VERSION ""

NS_ :

BS_:

BU_: CGW CLU EPB FCA SCC FR_CMR FR_RDR ADAS_PRK AMP BCW LDW_LKA MDPS RVM HUD AVM ACU ESC AFS

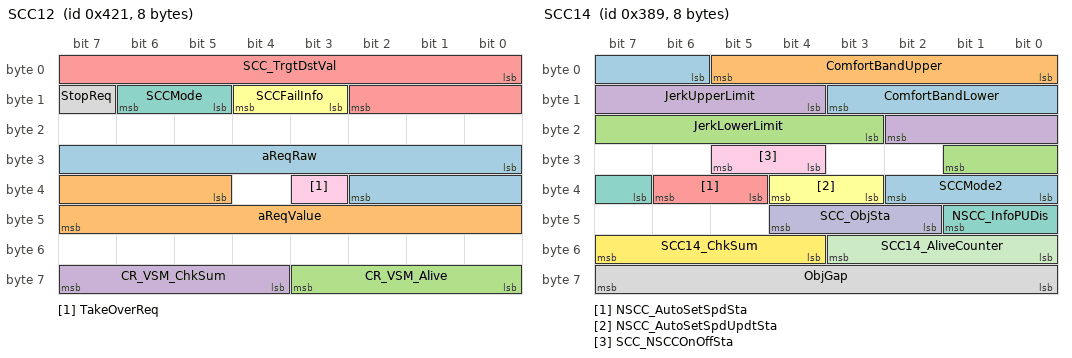
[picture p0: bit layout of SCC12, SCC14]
BO_ 1057 SCC12: 8 SCC
 SG_ aReqRaw : 24|11@1+ (0.01,-10.23) [-10.23|10.24] "m/s^2"  CGW,ESC,FR_CMR
 SG_ aReqValue : 37|11@1+ (0.01,-10.23) [-10.23|10.24] "m/s^2"  CGW,ESC,FR_CMR
 SG_ CR_VSM_Alive : 56|4@1+ (1,0) [0|15] ""  CGW,ESC,FR_CMR
 SG_ CR_VSM_ChkSum : 60|4@1+ (1,0) [0|15] ""  CGW,ESC,FR_CMR
 SG_ SCC_TrgtDstVal : 0|11@1+ (0.1,0) [0|204.7] "m"  CLU,FR_CMR
 SG_ SCCFailInfo : 11|2@1+ (1,0) [0|3] ""  ACU,CGW,CLU,ESC,LDW_LKA,FR_CMR
 SG_ SCCMode : 13|2@1+ (1,0) [0|3] ""  CGW,ESC,LDW_LKA,FR_CMR
 SG_ StopReq : 15|1@1+ (1,0) [0|1] ""  CGW,ESC,FR_CMR
 SG_ TakeOverReq : 35|1@1+ (1,0) [0|1] ""  CGW,CLU,ESC,FR_CMR

BO_ 1290 SCC13: 8 SCC
 SG_ SCC_Equip : 3|1@1+ (1,0) [0|1] ""  ESC,FR_CMR
 SG_ SCCDrvModeRValue : 0|3@1+ (1,0) [0|7] ""  CGW,FR_CMR

BO_ 905 SCC14: 8 SCC
 SG_ ComfortBandLower : 6|6@1+ (0.02,0) [0|1.26] "m/s^2"  ESC,FR_CMR
 SG_ ComfortBandUpper : 0|6@1+ (0.02,0) [0|1.26] "m/s^2"  ESC,FR_CMR
 SG_ JerkLowerLimit : 19|7@1+ (0.1,0) [0|12.7] "m/s^3"  ESC,FR_CMR
 SG_ JerkUpperLimit : 12|7@1+ (0.1,0) [0|12.7] "m/s^3"  ESC,FR_CMR
 SG_ NSCC_AutoSetSpdSta : 37|2@1+ (1,0) [0|1] ""  CGW,CLU,LDW_LKA,FR_CMR
 SG_ NSCC_AutoSetSpdUpdtSta : 35|2@1+ (1,0) [0|1] ""  CGW,CLU,FR_CMR
 SG_ NSCC_InfoPUDis : 39|3@1+ (1,0) [0|7] ""  CGW,CLU,FR_CMR
 SG_ ObjGap : 56|8@1+ (1,0) [0|255] ""  CGW,CLU,ESC,FR_CMR
 SG_ SCC_NSCCOnOffSta : 28|2@1+ (1,0) [0|3] ""  CGW,CLU,FR_CMR
 SG_ SCC_ObjSta : 42|3@1+ (1,0) [0|7] ""  CLU,FR_CMR
 SG_ SCC14_AliveCounter : 48|4@1+ (1,0) [0|15] ""  FR_CMR
 SG_ SCC14_ChkSum : 52|4@1+ (1,0) [0|15] ""  FR_CMR
 SG_ SCCMode2 : 32|3@1+ (1,0) [0|7] ""  ACU,CGW,CLU,ESC,LDW_LKA,FR_CMR

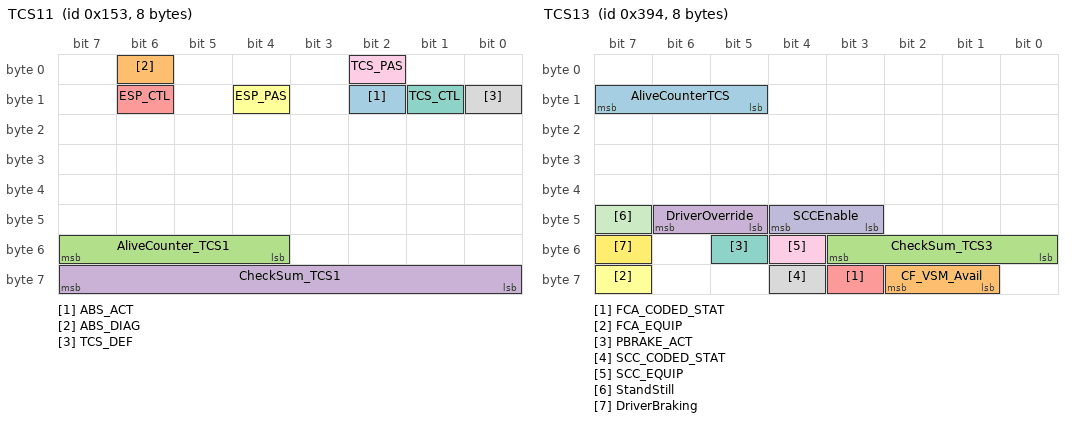
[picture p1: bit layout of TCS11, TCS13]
BO_ 339 TCS11: 8 ESC
 SG_ ABS_ACT : 10|1@1+ (1,0) [0|1] ""  ADAS_PRK,BCW,CGW,EPB,FCA,LDW_LKA,SCC,FR_CMR,FR_RDR
 SG_ ABS_DIAG : 6|1@1+ (1,0) [0|1] ""  ADAS_PRK,BCW,CGW,EPB,FCA,LDW_LKA,SCC,FR_CMR,FR_RDR
 SG_ AliveCounter_TCS1 : 52|4@1+ (1,0) [0|14] ""  CGW,EPB,FCA,SCC,FR_CMR,FR_RDR
 SG_ CheckSum_TCS1 : 56|8@1+ (1,0) [0|255] ""  CGW,EPB,FCA,SCC,FR_CMR,FR_RDR
 SG_ ESP_CTL : 14|1@1+ (1,0) [0|1] ""  ADAS_PRK,BCW,CGW,EPB,FCA,LDW_LKA,SCC,FR_CMR,FR_RDR
 SG_ ESP_PAS : 12|1@1+ (1,0) [0|1] ""  ADAS_PRK,CGW,EPB,FCA,SCC,FR_CMR,FR_RDR
 SG_ TCS_CTL : 9|1@1+ (1,0) [0|1] ""  ADAS_PRK,BCW,CGW,EPB,FCA,LDW_LKA,SCC,FR_CMR,FR_RDR
 SG_ TCS_DEF : 8|1@1+ (1,0) [0|1] ""  ADAS_PRK,CGW,EPB,LDW_LKA,FR_CMR,FR_RDR
 SG_ TCS_PAS : 2|1@1+ (1,0) [0|1] ""  ADAS_PRK,CGW,LDW_LKA,SCC,FR_CMR,FR_RDR

BO_ 916 TCS13: 8 ESC
 SG_ AliveCounterTCS : 13|3@1+ (1,0) [0|7] ""  CGW,FCA,SCC,FR_CMR,FR_RDR
 SG_ CF_VSM_Avail : 57|2@1+ (1,0) [0|3] ""  CGW,FCA,FR_CMR,FR_RDR
 SG_ CheckSum_TCS3 : 48|4@1+ (1,0) [0|15] ""  CGW,FCA,SCC,FR_CMR,FR_RDR
 SG_ DriverOverride : 45|2@1+ (1,0) [0|3] ""  CGW,FCA,LDW_LKA,SCC,FR_CMR,FR_RDR
 SG_ FCA_CODED_STAT : 59|1@1+ (1,0) [0|1] ""  FCA,FR_CMR,FR_RDR
 SG_ FCA_EQUIP : 63|1@1+ (1,0) [0|1] ""  FCA,FR_CMR,FR_RDR
 SG_ PBRAKE_ACT : 53|1@1+ (1,0) [0|1] ""  BCW,CGW,SCC,FR_CMR,FR_RDR
 SG_ SCC_CODED_STAT : 60|1@1+ (1,0) [0|1] ""  SCC,FR_CMR,FR_RDR
 SG_ SCC_EQUIP : 52|1@1+ (1,0) [0|1] ""  CGW,SCC,FR_CMR,FR_RDR
 SG_ SCCEnable : 43|2@1+ (1,0) [0|3] ""  CGW,SCC,FR_CMR,FR_RDR
 SG_ StandStill : 47|1@1+ (1,0) [0|1] ""  FR_CMR,FR_RDR
 SG_ DriverBraking : 55|1@1+ (1,0) [0|1] ""  FR_CMR,SCC,FR_RDR

BO_ 356 VSM11_FS: 4 ESC
 SG_ CF_Esc_Act : 12|1@1+ (1,0) [0|1] ""  CGW,LDW_LKA,MDPS,FR_CMR
 SG_ CRC : 24|8@1+ (1,0) [0|255] ""  CGW,LDW_LKA,MDPS,FR_CMR

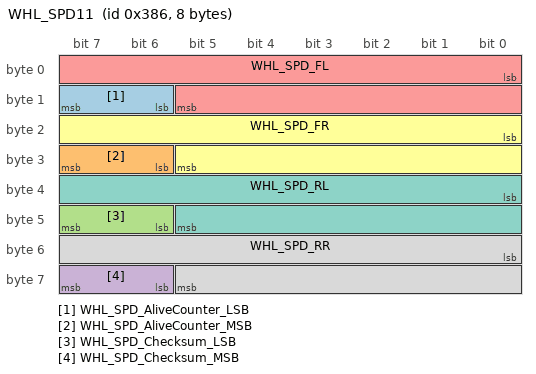
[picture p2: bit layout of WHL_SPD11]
BO_ 902 WHL_SPD11: 8 CGW
 SG_ WHL_SPD_AliveCounter_LSB : 14|2@1+ (1,0) [0|3] ""  ADAS_PRK,FCA,LDW_LKA,MDPS,FR_CMR,FR_RDR
 SG_ WHL_SPD_AliveCounter_MSB : 30|2@1+ (1,0) [0|3] ""  ADAS_PRK,FCA,LDW_LKA,MDPS,FR_CMR,FR_RDR
 SG_ WHL_SPD_Checksum_LSB : 46|2@1+ (1,0) [0|3] ""  ADAS_PRK,FCA,LDW_LKA,MDPS,FR_CMR,FR_RDR
 SG_ WHL_SPD_Checksum_MSB : 62|2@1+ (1,0) [0|3] ""  ADAS_PRK,FCA,LDW_LKA,MDPS,FR_CMR,FR_RDR
 SG_ WHL_SPD_FL : 0|14@1+ (0.03125,0) [0|511.96875] "km/h"  ADAS_PRK,BCW,CLU,FCA,LDW_LKA,MDPS,RVM,SCC,FR_CMR,FR_RDR
 SG_ WHL_SPD_FR : 16|14@1+ (0.03125,0) [0|511.96875] "km/h"  ADAS_PRK,BCW,CLU,FCA,LDW_LKA,MDPS,RVM,SCC,FR_CMR,FR_RDR
 SG_ WHL_SPD_RL : 32|14@1+ (0.03125,0) [0|511.96875] "km/h"  ADAS_PRK,BCW,CLU,FCA,LDW_LKA,MDPS,RVM,SCC,FR_CMR,FR_RDR
 SG_ WHL_SPD_RR : 48|14@1+ (0.03125,0) [0|511.96875] "km/h"  ADAS_PRK,BCW,CLU,FCA,LDW_LKA,MDPS,RVM,SCC,FR_CMR,FR_RDR

BO_ 1728 XCP_Rx_Pdu: 8 Vector__XXX
 SG_ XCP_Rx_Data : 0|64@1+ (1,0) [0|1.84467440737096E+019] ""  FR_CMR

BO_ 1729 XCP_Tx_Pdu: 8 FR_CMR
 SG_ XCP_Tx_Data : 0|64@1+ (1,0) [0|1.84467440737096E+019] "" Vector__XXX

CM_ BO_ 1057 "[P] Periodic";
CM_ SG_ 1057 aReqRaw "SCC acceleration requirement without Jerk limit";
CM_ SG_ 1057 aReqValue "SCC acceleration requirement with Jerk limit";
CM_ SG_ 1057 CR_VSM_Alive "SCC12 Message Alive-counter";
CM_ SG_ 1057 CR_VSM_ChkSum "SCC12 Message Checksum";
CM_ SG_ 1057 SCC_TrgtDstVal "SCC_TargetDistanceValue";
CM_ SG_ 1057 SCCFailInfo "Indication of SCC-malfunction";
CM_ SG_ 1057 SCCMode "Status of SCC-SCU";
CM_ SG_ 1057 StopReq "Stop request flag";
CM_ SG_ 1057 TakeOverReq "Take-over request";
CM_ BO_ 1290 "[PE] Periodic and On Event";
CM_ SG_ 1290 SCC_Equip "SCC Equipment Status";
CM_ SG_ 1290 SCCDrvModeRValue "Drive mode return value";
CM_ BO_ 905 "[P] Periodic";
CM_ SG_ 905 ComfortBandLower "Lower limit for comfort band";
CM_ SG_ 905 ComfortBandUpper "Upper limit for comfort band";
CM_ SG_ 905 JerkLowerLimit "Maximum negative jerk";
CM_ SG_ 905 JerkUpperLimit "Maximum positive jerk";
CM_ SG_ 905 NSCC_AutoSetSpdSta "NSCC_AutoSetSpeedStatus ##2G##LDW_LKA - HDA11 - CF_HDA_AutoSetSpdEnable";
CM_ SG_ 905 NSCC_AutoSetSpdUpdtSta "NSCC_AutoSetSpeedUpdateStatus ##2G##LDW_LKA - HDA11 - CF_HDA_AutoSetSpdUpdate";
CM_ SG_ 905 NSCC_InfoPUDis "NSCC_InformationPopUpDisplay";
CM_ SG_ 905 ObjGap "Target object distance";
CM_ SG_ 905 SCC_NSCCOnOffSta "SCC_NSCCOnOffSta";
CM_ SG_ 905 SCC_ObjSta "SCC_ObjectState";
CM_ SG_ 905 SCC14_AliveCounter "SCC14 Message Alive-counter";
CM_ SG_ 905 SCC14_ChkSum "SCC14 Message Checksum";
CM_ SG_ 905 SCCMode2 "Status of SCC-SCU";
CM_ BO_ 339 "[P] Periodic";
CM_ SG_ 339 ABS_ACT "ABS “control“ indication";
CM_ SG_ 339 ABS_DIAG "ABS/TCS/ESC “diagnostic mode” indication";
CM_ SG_ 339 AliveCounter_TCS1 "Alive-counter";
CM_ SG_ 339 CheckSum_TCS1 "CheckSum";
CM_ SG_ 339 ESP_CTL "ESC “control“ indication";
CM_ SG_ 339 ESP_PAS "ESC disabled by user";
CM_ SG_ 339 TCS_CTL "TCS control indication";
CM_ SG_ 339 TCS_DEF "TCS defective indication";
CM_ SG_ 339 TCS_PAS "TCS disabled by user";
CM_ BO_ 916 "[P] Periodic";
CM_ SG_ 916 AliveCounterTCS "Alive rolling counter";
CM_ SG_ 916 CF_VSM_Avail "Flag which tells if ESC is available for VSM or not";
CM_ SG_ 916 CheckSum_TCS3 "Signal checksum";
CM_ SG_ 916 DriverOverride "Driver is requesting more acceleration / deceleration than SCC";
CM_ SG_ 916 FCA_CODED_STAT "This signal indicates coding status for FCA";
CM_ SG_ 916 FCA_EQUIP "This signal indicates equipment for FCA";
CM_ SG_ 916 PBRAKE_ACT "Parking brake active";
CM_ SG_ 916 SCC_CODED_STAT "This signal indicates coding status for SCC";
CM_ SG_ 916 SCC_EQUIP "SCC Option Description";
CM_ SG_ 916 SCCEnable "SCC acceleration/deceleration requests enabled";
CM_ SG_ 916 StandStill "StandStill";
CM_ SG_ 916 DriverBraking "DriverBraking";
CM_ BO_ 356 "[P] Periodic";
CM_ SG_ 356 CF_Esc_Act "VSM active";
CM_ SG_ 356 CRC "Cyclic Redundancy Check(CRC)";
CM_ BO_ 902 "[P] Periodic";
CM_ SG_ 902 WHL_SPD_AliveCounter_LSB "Message counter";
CM_ SG_ 902 WHL_SPD_AliveCounter_MSB "Message counter";
CM_ SG_ 902 WHL_SPD_Checksum_LSB "Checksum";
CM_ SG_ 902 WHL_SPD_Checksum_MSB "Checksum";
CM_ SG_ 902 WHL_SPD_FL "Wheel speed (high reolution), front, left-hand";
CM_ SG_ 902 WHL_SPD_FR "Wheel speed (high reolution), front, right-hand";
CM_ SG_ 902 WHL_SPD_RL "Wheel speed (high reolution), rear, left-hand";
CM_ SG_ 902 WHL_SPD_RR "Wheel speed (high reolution), rear, right-hand";
CM_ BO_ 1728 "[EW] On Event and On Write";
CM_ SG_ 1728 XCP_Rx_Data "XCP_Rx_Data";
CM_ BO_ 1729 "[EW] On Event and On Write";
CM_ SG_ 1729 XCP_Tx_Data "XCP_Tx_Data";
BA_DEF_ BO_  "GenMsgILSupport" ENUM  "No","Yes";
BA_DEF_ BO_  "DiagRequest" ENUM  "No","Yes";
BA_DEF_ BO_  "DiagResponse" ENUM  "No","Yes";
BA_DEF_ BO_  "DiagState" ENUM  "No","Yes";
BA_DEF_ BO_  "VFrameFormat" ENUM  "StandardCAN","ExtendedCAN","reserved","reserved","reserved","reserved","reserved","reserved","reserved","reserved","reserved","reserved","reserved","reserved","StandardCAN_FD","ExtendedCAN_FD";
BA_DEF_ BO_  "GenMsgSendType" ENUM  "Cyclic","NoMsgSendType";
BA_DEF_ SG_  "UserSigValidity" ENUM  "B+","ACC","IG","IG1","IG2","IG3","IG1 or IG2","IG1 or IG3","Undef";
BA_DEF_ SG_  "RoutingFactor" INT 1 1215752192;
BA_DEF_ SG_  "Description" STRING ;
BA_DEF_ SG_  "Version" STRING ;
BA_DEF_ BO_  "GenMsgCycleTime" INT 0 2000;
BA_DEF_ BO_  "GenMsgStartDelayTime" INT 0 2000;
BA_DEF_ SG_  "UsrSigPurpose" ENUM  "Undef","FN","DIAG","DEV","NM";
BA_DEF_ SG_  "GenSigStartValue" INT 0 0;
BA_DEF_DEF_  "GenMsgILSupport" "Yes";
BA_DEF_DEF_  "DiagRequest" "No";
BA_DEF_DEF_  "DiagResponse" "No";
BA_DEF_DEF_  "DiagState" "No";
BA_DEF_DEF_  "VFrameFormat" "";
BA_DEF_DEF_  "GenMsgSendType" "NoMsgSendType";
BA_DEF_DEF_  "UserSigValidity" "IG";
BA_DEF_DEF_  "RoutingFactor" 1;
BA_DEF_DEF_  "Description" "";
BA_DEF_DEF_  "Version" "";
BA_DEF_DEF_  "GenMsgCycleTime" 0;
BA_DEF_DEF_  "GenMsgStartDelayTime" 0;
BA_DEF_DEF_  "UsrSigPurpose" "FN";
BA_DEF_DEF_  "GenSigStartValue" 0;
BA_ "GenMsgCycleTime" BO_ 1057 20;
BA_ "GenMsgSendType" BO_ 1057 0;
BA_ "VFrameFormat" BO_ 1057 0;
BA_ "GenMsgCycleTime" BO_ 1290 200;
BA_ "GenMsgSendType" BO_ 1290 0;
BA_ "VFrameFormat" BO_ 1290 0;
BA_ "GenMsgCycleTime" BO_ 905 20;
BA_ "GenMsgSendType" BO_ 905 0;
BA_ "VFrameFormat" BO_ 905 0;
BA_ "GenMsgCycleTime" BO_ 339 10;
BA_ "GenMsgSendType" BO_ 339 0;
BA_ "VFrameFormat" BO_ 339 0;
BA_ "GenMsgCycleTime" BO_ 916 20;
BA_ "GenMsgSendType" BO_ 916 0;
BA_ "VFrameFormat" BO_ 916 0;
BA_ "GenMsgCycleTime" BO_ 356 10;
BA_ "GenMsgSendType" BO_ 356 0;
BA_ "VFrameFormat" BO_ 356 0;
BA_ "GenMsgCycleTime" BO_ 902 20;
BA_ "GenMsgSendType" BO_ 902 0;
BA_ "VFrameFormat" BO_ 902 0;
BA_ "GenMsgILSupport" BO_ 1728 0;
BA_ "VFrameFormat" BO_ 1728 0;
BA_ "GenMsgILSupport" BO_ 1729 0;
BA_ "VFrameFormat" BO_ 1729 0;
BA_ "UserSigValidity" SG_ 1057 aReqRaw 3;
BA_ "Description" SG_ 1057 aReqRaw "SCC acceleration requirement without Jerk limit (m/s2)_x000D_

";
BA_ "Version" SG_ 1057 aReqRaw "2.51.05";
BA_ "UserSigValidity" SG_ 1057 aReqValue 3;
BA_ "Description" SG_ 1057 aReqValue "SCC acceleration requirement with Jerk limit (m/s2)_x000D_

";
BA_ "Version" SG_ 1057 aReqValue "2.51.05";
BA_ "UserSigValidity" SG_ 1057 CR_VSM_Alive 3;
BA_ "Description" SG_ 1057 CR_VSM_Alive "This signal indicates Message counter (alive-counter) for robustness._x000D_

_x000D_

0 … 14 : After the counter is 14 it starts again at 0._x000D_

15 : signal invalid";
BA_ "Version" SG_ 1057 CR_VSM_Alive "2.48.06";
BA_ "UserSigValidity" SG_ 1057 CR_VSM_ChkSum 3;
BA_ "Description" SG_ 1057 CR_VSM_ChkSum "This signal indicates Checksum for robustness.



(PH) = 10h - (least significant nibbles of (Byte0 + Byte1 + Byte2 + Byte3 + Byte4 + Byte5 + Byte6 + Byte7) + most significant nibbles of (Byte0 + Byte1 + Byte2 + Byte3 + Byte4 + Byte5 + Byte6))";
BA_ "Version" SG_ 1057 CR_VSM_ChkSum "2.48.06";
BA_ "UserSigValidity" SG_ 1057 SCC_TrgtDstVal 3;
BA_ "GenSigStartValue" SG_ 1057 SCC_TrgtDstVal 2046;
BA_ "Description" SG_ 1057 SCC_TrgtDstVal "This signal provides the target distance for SCC fallowing control.

- SCC 거리 제어를 위한 목표 차간 거리 정보";
BA_ "Version" SG_ 1057 SCC_TrgtDstVal "2.67.03";
BA_ "UserSigValidity" SG_ 1057 SCCFailInfo 3;
BA_ "Description" SG_ 1057 SCCFailInfo "This signal is evaluated by the driver information device to release the failure information to the driver. If this signal is set to anything other than 0, the TCS/ESC shall ignore any requests from SCC.";
BA_ "Version" SG_ 1057 SCCFailInfo "2.48.06";
BA_ "UserSigValidity" SG_ 1057 SCCMode 3;
BA_ "GenSigStartValue" SG_ 1057 SCCMode 3;
BA_ "Description" SG_ 1057 SCCMode "The signal SCCMode specifies the operational mode of SCC";
BA_ "Version" SG_ 1057 SCCMode "2.69.01";
BA_ "UserSigValidity" SG_ 1057 StopReq 3;
BA_ "Description" SG_ 1057 StopReq "A control request flag for vehicle stop. SCC expects vehicle to be controlled to a complete stop and hold its state.";
BA_ "Version" SG_ 1057 StopReq "2.00.00";
BA_ "UserSigValidity" SG_ 1057 TakeOverReq 3;
BA_ "Description" SG_ 1057 TakeOverReq "The Take-over Request supports the driver to identify the limits of the SCC control. Reasons for such a request may be:



- Deceleration capability insufficient for the current situation.



Clutch actuation by the driver is necessary to avoid stopping ";
BA_ "Version" SG_ 1057 TakeOverReq "2.00.00";
BA_ "UserSigValidity" SG_ 1290 SCC_Equip 3;
BA_ "Description" SG_ 1290 SCC_Equip "This signal indicates equipment for SCC";
BA_ "Version" SG_ 1290 SCC_Equip "2.26.00";
BA_ "UserSigValidity" SG_ 1290 SCCDrvModeRValue 3;
BA_ "GenSigStartValue" SG_ 1290 SCCDrvModeRValue 2;
BA_ "Description" SG_ 1290 SCCDrvModeRValue "Drive mode return value";
BA_ "Version" SG_ 1290 SCCDrvModeRValue "2.50.02";
BA_ "UserSigValidity" SG_ 905 ComfortBandLower 3;
BA_ "Description" SG_ 905 ComfortBandLower "This signal informs the transmission control about the lower limit for the comfort band. Within this band the actual deceleration can deviate from the command value to avoid unwanted effects such as unnecessary shift downs. _x000D_

_x000D_

0 : Precise ";
BA_ "Version" SG_ 905 ComfortBandLower "2.51.03";
BA_ "UserSigValidity" SG_ 905 ComfortBandUpper 3;
BA_ "Description" SG_ 905 ComfortBandUpper "This signal informs the transmission control about the upper limit for the comfort band. Within this band the actual deceleration can deviate from the command value to avoid unwanted effects such as unnecessary shift downs. _x000D_

_x000D_

0 : Precise ";
BA_ "Version" SG_ 905 ComfortBandUpper "2.51.03";
BA_ "UserSigValidity" SG_ 905 JerkLowerLimit 3;
BA_ "Description" SG_ 905 JerkLowerLimit "The signal informs the external longitudinal controller about the maximum negative jerk which is_x000D_

possible to realize the commanded acceleration aReqRaw. Under given circumstances the external longitudinal controller_x000D_

may increase this valu";
BA_ "Version" SG_ 905 JerkLowerLimit "2.51.03";
BA_ "UserSigValidity" SG_ 905 JerkUpperLimit 3;
BA_ "Description" SG_ 905 JerkUpperLimit "The signal informs the external longitudinal controller about the maximum positive jerk which is_x000D_

possible to realize the commanded acceleration aReqRaw. Under given circumstances the external longitudinal controller_x000D_

may increase this valu";
BA_ "Version" SG_ 905 JerkUpperLimit "2.51.03";
BA_ "UserSigValidity" SG_ 905 NSCC_AutoSetSpdSta 3;
BA_ "Description" SG_ 905 NSCC_AutoSetSpdSta "This is information if Auto Set Speed Control is enable or not.";
BA_ "Version" SG_ 905 NSCC_AutoSetSpdSta "2.64.04";
BA_ "UserSigValidity" SG_ 905 NSCC_AutoSetSpdUpdtSta 3;
BA_ "Description" SG_ 905 NSCC_AutoSetSpdUpdtSta "This is information if Auto Set Speed Control is updated or not.";
BA_ "Version" SG_ 905 NSCC_AutoSetSpdUpdtSta "2.64.04";
BA_ "UserSigValidity" SG_ 905 NSCC_InfoPUDis 3;
BA_ "Description" SG_ 905 NSCC_InfoPUDis "This signal shows the cluster pop-up for NSCC Information";
BA_ "Version" SG_ 905 NSCC_InfoPUDis "2.64.04";
BA_ "UserSigValidity" SG_ 905 ObjGap 3;
BA_ "Description" SG_ 905 ObjGap "If a in-path object is recognized by SCC, the driver should be informed._x000D_

And object distance level is informed also.";
BA_ "Version" SG_ 905 ObjGap "2.45.03";
BA_ "UserSigValidity" SG_ 905 SCC_NSCCOnOffSta 3;
BA_ "Description" SG_ 905 SCC_NSCCOnOffSta "This signal describes the on/off status of NSCC-Z/C/R and HDA Auto-set function.



NSCC-Z/C/R and HDA auto-set on/off 상태 정보";
BA_ "Version" SG_ 905 SCC_NSCCOnOffSta "2.67.03";
BA_ "UserSigValidity" SG_ 905 SCC_ObjSta 3;
BA_ "Description" SG_ 905 SCC_ObjSta "This signal represents the state of in-path object and information of controllable state.

- 자차선상의 전방 차량 인식 여부 및 제어가능 상태 정보";
BA_ "Version" SG_ 905 SCC_ObjSta "2.67.03";
BA_ "UserSigValidity" SG_ 905 SCC14_AliveCounter 3;
BA_ "Description" SG_ 905 SCC14_AliveCounter "This signal indicates Message counter (alive-counter) for robustness.



0 … 14 : After the counter is 14 it starts again at 0.

15 : signal invalid";
BA_ "Version" SG_ 905 SCC14_AliveCounter "2.65.05";
BA_ "UserSigValidity" SG_ 905 SCC14_ChkSum 3;
BA_ "Description" SG_ 905 SCC14_ChkSum "This signal indicates Checksum for robustness.



(PH) = 10h - (least significant nibbles of (Byte0 + Byte1 + Byte2 + Byte3 + Byte4 + Byte5 + Byte6 + Byte7) + most significant nibbles of (Byte0 + Byte1 + Byte2 + Byte3 + Byte4 + Byte5 + Byte7))";
BA_ "Version" SG_ 905 SCC14_ChkSum "2.65.05";
BA_ "UserSigValidity" SG_ 905 SCCMode2 3;
BA_ "GenSigStartValue" SG_ 905 SCCMode2 3;
BA_ "Description" SG_ 905 SCCMode2 "The signal SCCMode specifies the operational mode of SCC";
BA_ "Version" SG_ 905 SCCMode2 "2.69.01";
BA_ "UserSigValidity" SG_ 339 ABS_ACT 3;
BA_ "Description" SG_ 339 ABS_ACT "ABS controller provides an information on ABS Active signal.



ABS_ACT signal is 1 during the ABS control and if it is not ABS control phase this value is 0.

";
BA_ "Version" SG_ 339 ABS_ACT "2.00.00";
BA_ "UserSigValidity" SG_ 339 ABS_DIAG 3;
BA_ "Description" SG_ 339 ABS_DIAG "Information regarding the ABS/TCS/ESC “diagnostic mode” indication.";
BA_ "Version" SG_ 339 ABS_DIAG "2.00.00";
BA_ "UserSigValidity" SG_ 339 AliveCounter_TCS1 3;
BA_ "Description" SG_ 339 AliveCounter_TCS1 "Alive-counter which is increasing every loop.

The alive-counter becomes 00H at the next loop when it is 0EH

";
BA_ "Version" SG_ 339 AliveCounter_TCS1 "2.08.02";
BA_ "UserSigValidity" SG_ 339 CheckSum_TCS1 3;
BA_ "Description" SG_ 339 CheckSum_TCS1 "This value is used to check the TCS1 message is correctly transmitted.



(PH) = Byte(Byte0 + Byte1 + Byte2 + Byte3 + Byte4 + Byte5 + Byte6)";
BA_ "Version" SG_ 339 CheckSum_TCS1 "2.08.02";
BA_ "UserSigValidity" SG_ 339 ESP_CTL 3;
BA_ "Description" SG_ 339 ESP_CTL "Information regarding the ESC 'control' indication.



Conversion:

1. ESP_DEF(0)/ESP_PAS(0)/ESP_CTL(0) -> ESC lamp OFF

2. ESP_DEF(0)/ESP_PAS(0)/ESP_CTL(1) -> ESC active

3. ESP_DEF(0)/ESP_PAS(1)/ESP_CTL(x) -> ESC disabled by user (SW off)

4. ESP_DEF(1";
BA_ "Version" SG_ 339 ESP_CTL "2.00.00";
BA_ "UserSigValidity" SG_ 339 ESP_PAS 3;
BA_ "Description" SG_ 339 ESP_PAS "Information regarding the ESC 'enable/disable' indication.



Conversion:

1. ESP_DEF(0)/ESP_PAS(0)/ESP_CTL(0) -> ESC lamp OFF

2. ESP_DEF(0)/ESP_PAS(0)/ESP_CTL(1) -> ESC active

3. ESP_DEF(0)/ESP_PAS(1)/ESP_CTL(x) -> ESC disabled by user (SW off)

4. ES";
BA_ "Version" SG_ 339 ESP_PAS "2.00.00";
BA_ "UserSigValidity" SG_ 339 TCS_CTL 3;
BA_ "Description" SG_ 339 TCS_CTL "Information regarding the TCS 'control' indication.



Conversion :

1. TCS_DEF(0)/TCS_PAS(0)/TCS_CTL(0) -> TCS lamp OFF

2. TCS_DEF(0)/TCS_PAS(0)/TCS_CTL(1) -> TCS Active

3. TCS_DEF(0)/TCS_PAS(1)/TCS_CTL(x) -> TCS is disabled by user

4. TCS_DEF(1)/TCS";
BA_ "Version" SG_ 339 TCS_CTL "2.00.00";
BA_ "UserSigValidity" SG_ 339 TCS_DEF 3;
BA_ "Description" SG_ 339 TCS_DEF "Information regarding the TCS 'defective' indication.



Conversion :

1. TCS_DEF(0)/TCS_PAS(0)/TCS_CTL(0) -> TCS lamp OFF

2. TCS_DEF(0)/TCS_PAS(0)/TCS_CTL(1) -> TCS Active

3. TCS_DEF(0)/TCS_PAS(1)/TCS_CTL(x) -> TCS is disabled by user

4. TCS_DEF(1)/T";
BA_ "Version" SG_ 339 TCS_DEF "2.00.00";
BA_ "UserSigValidity" SG_ 339 TCS_PAS 3;
BA_ "Description" SG_ 339 TCS_PAS "Information regarding the TCS 'enable/disable' indication.



Conversion :

1. TCS_DEF(0)/TCS_PAS(0)/TCS_CTL(0) -> TCS lamp OFF

2. TCS_DEF(0)/TCS_PAS(0)/TCS_CTL(1) -> TCS Active

3. TCS_DEF(0)/TCS_PAS(1)/TCS_CTL(x) -> TCS is disabled by user

4. TCS_DEF";
BA_ "Version" SG_ 339 TCS_PAS "2.00.00";
BA_ "UserSigValidity" SG_ 916 AliveCounterTCS 3;
BA_ "Description" SG_ 916 AliveCounterTCS "This signal is incremented with each TCS3 message sent. This signal enables subsystems which are using signals from TCS3 to check whether the TCS3 message is updated or not.";
BA_ "Version" SG_ 916 AliveCounterTCS "2.00.00";
BA_ "UserSigValidity" SG_ 916 CF_VSM_Avail 3;
BA_ "Description" SG_ 916 CF_VSM_Avail "This signal indicates state signal from ESC to SCC or FCA which tells if ESC is “Available”,_x000D_

“Temporarily not Available”, “Permanently not Available” or 'FCA Communication Error'.";
BA_ "Version" SG_ 916 CF_VSM_Avail "2.50.03";
BA_ "UserSigValidity" SG_ 916 CheckSum_TCS3 3;
BA_ "Description" SG_ 916 CheckSum_TCS3 "This value is used to check the TCS3 message is correctly transmitted.



(PH) = 10H - (Least Significant Nibbles of (Byte0 + Byte1 + Byte2 + Byte3 + Byte 4 + Byte5) + Most Significant Nibbles of (Byte0 + Byte1 + Byte2 + Byte3 + Byte4 + Byte5 + Byte6))";
BA_ "Version" SG_ 916 CheckSum_TCS3 "2.00.00";
BA_ "UserSigValidity" SG_ 916 DriverOverride 3;
BA_ "Description" SG_ 916 DriverOverride "This signal indicates that acceleration or deceleration value of driver’s requirement is greater than SCC setting value.";
BA_ "Version" SG_ 916 DriverOverride "2.00.00";
BA_ "UserSigValidity" SG_ 916 FCA_CODED_STAT 3;
BA_ "Description" SG_ 916 FCA_CODED_STAT "ESC's FCA Function Variant Coding Status.

Do not recognize 0x0(Not Coded) as failure.";
BA_ "Version" SG_ 916 FCA_CODED_STAT "2.66.06";
BA_ "UserSigValidity" SG_ 916 FCA_EQUIP 3;
BA_ "Description" SG_ 916 FCA_EQUIP "FCA Equipment Status";
BA_ "Version" SG_ 916 FCA_EQUIP "2.46.08";
BA_ "UserSigValidity" SG_ 916 PBRAKE_ACT 3;
BA_ "Description" SG_ 916 PBRAKE_ACT "This signal indicates whether the parking brake is activated or not.";
BA_ "Version" SG_ 916 PBRAKE_ACT "2.00.00";
BA_ "UserSigValidity" SG_ 916 SCC_CODED_STAT 3;
BA_ "Description" SG_ 916 SCC_CODED_STAT "ESC's SCC Function Variant Coding Status.

Do not recognize 0x0(Not Coded) as failure.";
BA_ "Version" SG_ 916 SCC_CODED_STAT "2.66.01";
BA_ "UserSigValidity" SG_ 916 SCC_EQUIP 3;
BA_ "Description" SG_ 916 SCC_EQUIP "This value is used for SCC is equipped or not.";
BA_ "Version" SG_ 916 SCC_EQUIP "2.50.04";
BA_ "UserSigValidity" SG_ 916 SCCEnable 3;
BA_ "Description" SG_ 916 SCCEnable "This signal is set by the safety logic in the TCS/ESC. The safety logic shall monitor the following:

1. A temporary failure in the vehicle does not allow SCC (Brakes are overheated, etc…). 

SCC is disabled reversible.

2. SCC communication failure (t";
BA_ "Version" SG_ 916 SCCEnable "2.50.04";
BA_ "UserSigValidity" SG_ 916 StandStill 3;
BA_ "Description" SG_ 916 StandStill "This signal represents Stand still status";
BA_ "Version" SG_ 916 StandStill "0.00.01";
BA_ "UserSigValidity" SG_ 916 DriverBraking 3;
BA_ "Description" SG_ 916 DriverBraking "This signal represents Brake pedal press status";
BA_ "Version" SG_ 916 DriverBraking "0.00.01";
BA_ "UserSigValidity" SG_ 356 CF_Esc_Act 3;
BA_ "Description" SG_ 356 CF_Esc_Act "ESC controller provides an information on VSM (ESC+MDPS) Active signal. It indicates VSM control is

active or inactive.";
BA_ "Version" SG_ 356 CF_Esc_Act "2.45.07";
BA_ "UserSigValidity" SG_ 356 CRC 3;
BA_ "GenSigStartValue" SG_ 356 CRC 255;
BA_ "Description" SG_ 356 CRC "Sender calculates CRC : _x000D_

The sender of safety relevant CAN output signals shall protect the output signals with a CRC on application software level._x000D_

_x000D_

Each CAN frame with safety relevant signals shall contain its own CRC._x000D_

�";
BA_ "Version" SG_ 356 CRC "2.45.07";
BA_ "UserSigValidity" SG_ 902 WHL_SPD_AliveCounter_LSB 3;
BA_ "Description" SG_ 902 WHL_SPD_AliveCounter_LSB "This signal indicates message counter (alive-counter) for robustness._x000D_

_x000D_

* 0 to15 rolling count ; increases by 1 at every sampling count(20ms)_x000D_

* after the counter is 15, it starts again at 0_x000D_

* LSB, 2bits";
BA_ "Version" SG_ 902 WHL_SPD_AliveCounter_LSB "2.48.06";
BA_ "UserSigValidity" SG_ 902 WHL_SPD_AliveCounter_MSB 3;
BA_ "Description" SG_ 902 WHL_SPD_AliveCounter_MSB "This signal indicates message counter (alive-counter) for robustness._x000D_

_x000D_

* 0 to15 rolling count ; increases by 1 at every sampling count(20ms)_x000D_

* after the counter is 15, it starts again at 1_x000D_

* MSB, 2bits";
BA_ "Version" SG_ 902 WHL_SPD_AliveCounter_MSB "2.48.06";
BA_ "UserSigValidity" SG_ 902 WHL_SPD_Checksum_LSB 3;
BA_ "Description" SG_ 902 WHL_SPD_Checksum_LSB "This value is used to check the WHL_SPD11 message is correctly transmitted._x000D_

(PH) = [ (Bit 0 + ... Bit13) + (Bit 16 + ... Bit 29) + (Bit 32 + ... Bit 45) + (Bit 48 + ... Bit 61) ] XOR [ 0x9h ]_x000D_

* LSB, 2bits";
BA_ "Version" SG_ 902 WHL_SPD_Checksum_LSB "2.48.06";
BA_ "UserSigValidity" SG_ 902 WHL_SPD_Checksum_MSB 3;
BA_ "Description" SG_ 902 WHL_SPD_Checksum_MSB "This value is used to check the WHL_SPD11 message is correctly transmitted._x000D_

(PH) = [ (Bit 0 + ... Bit13) + (Bit 16 + ... Bit 29) + (Bit 32 + ... Bit 45) + (Bit 48 + ... Bit 61) ] XOR [ 0x9h ]";
BA_ "Version" SG_ 902 WHL_SPD_Checksum_MSB "2.48.06";
BA_ "UserSigValidity" SG_ 902 WHL_SPD_FL 3;
BA_ "Description" SG_ 902 WHL_SPD_FL "This signal provides the wheel velocity of each wheel and have 14 bits length and a resolution of 0.03125 km/h.(This resolution is higher than that of signal in TCS5).

In case of failure of one wheel speed sensor, the value 3FFFH is used as error identi";
BA_ "Version" SG_ 902 WHL_SPD_FL "2.13.00";
BA_ "UserSigValidity" SG_ 902 WHL_SPD_FR 3;
BA_ "Description" SG_ 902 WHL_SPD_FR "This signal provides the wheel velocity of each wheel and have 14 bits length and a resolution of 0.03125 km/h.(This resolution is higher than that of signal in TCS5).

In case of failure of one wheel speed sensor, the value 3FFFH is used as error identi";
BA_ "Version" SG_ 902 WHL_SPD_FR "2.13.00";
BA_ "UserSigValidity" SG_ 902 WHL_SPD_RL 3;
BA_ "Description" SG_ 902 WHL_SPD_RL "This signal provides the wheel velocity of each wheel and have 14 bits length and a resolution of 0.03125 km/h.(This resolution is higher than that of signal in TCS5).

In case of failure of one wheel speed sensor, the value 3FFFH is used as error identi";
BA_ "Version" SG_ 902 WHL_SPD_RL "2.13.00";
BA_ "UserSigValidity" SG_ 902 WHL_SPD_RR 3;
BA_ "Description" SG_ 902 WHL_SPD_RR "This signal provides the wheel velocity of each wheel and have 14 bits length and a resolution of 0.03125 km/h.(This resolution is higher than that of signal in TCS5).

In case of failure of one wheel speed sensor, the value 3FFFH is used as error identi";
BA_ "Version" SG_ 902 WHL_SPD_RR "2.13.00";
BA_ "UserSigValidity" SG_ 1728 XCP_Rx_Data 3;
BA_ "Description" SG_ 1728 XCP_Rx_Data "-";
BA_ "Version" SG_ 1728 XCP_Rx_Data "0.00.01";
BA_ "UsrSigPurpose" SG_ 1728 XCP_Rx_Data 2;
BA_ "UserSigValidity" SG_ 1729 XCP_Tx_Data 3;
BA_ "Description" SG_ 1729 XCP_Tx_Data "-";
BA_ "Version" SG_ 1729 XCP_Tx_Data "0.00.01";
BA_ "UsrSigPurpose" SG_ 1729 XCP_Tx_Data 2;
VAL_ 1057 CR_VSM_Alive 15 "Signal Invalid" ;
VAL_ 1057 SCC_TrgtDstVal 1501 "Reserved" 1502 "Reserved" 1503 "Reserved" 1504 "Reserved" 1505 "Reserved" 1506 "Reserved" 1507 "Reserved" 1508 "Reserved" 1509 "Reserved" 1510 "Reserved" 1511 "Reserved" 1512 "Reserved" 1513 "Reserved" 1514 "Reserved" 1515 "Reserved" 1516 "Reserved" 1517 "Reserved" 1518 "Reserved" 1519 "Reserved" 1520 "Reserved" 1521 "Reserved" 1522 "Reserved" 1523 "Reserved" 1524 "Reserved" 1525 "Reserved" 1526 "Reserved" 1527 "Reserved" 1528 "Reserved" 1529 "Reserved" 1530 "Reserved" 1531 "Reserved" 1532 "Reserved" 1533 "Reserved" 1534 "Reserved" 1535 "Reserved" 1536 "Reserved" 1537 "Reserved" 1538 "Reserved" 1539 "Reserved" 1540 "Reserved" 1541 "Reserved" 1542 "Reserved" 1543 "Reserved" 1544 "Reserved" 1545 "Reserved" 1546 "Reserved" 1547 "Reserved" 1548 "Reserved" 1549 "Reserved" 1550 "Reserved" 1551 "Reserved" 1552 "Reserved" 1553 "Reserved" 1554 "Reserved" 1555 "Reserved" 1556 "Reserved" 1557 "Reserved" 1558 "Reserved" 1559 "Reserved" 1560 "Reserved" 1561 "Reserved" 1562 "Reserved" 1563 "Reserved" 1564 "Reserved" 1565 "Reserved" 1566 "Reserved" 1567 "Reserved" 1568 "Reserved" 1569 "Reserved" 1570 "Reserved" 1571 "Reserved" 1572 "Reserved" 1573 "Reserved" 1574 "Reserved" 1575 "Reserved" 1576 "Reserved" 1577 "Reserved" 1578 "Reserved" 1579 "Reserved" 1580 "Reserved" 1581 "Reserved" 1582 "Reserved" 1583 "Reserved" 1584 "Reserved" 1585 "Reserved" 1586 "Reserved" 1587 "Reserved" 1588 "Reserved" 1589 "Reserved" 1590 "Reserved" 1591 "Reserved" 1592 "Reserved" 1593 "Reserved" 1594 "Reserved" 1595 "Reserved" 1596 "Reserved" 1597 "Reserved" 1598 "Reserved" 1599 "Reserved" 1600 "Reserved" 1601 "Reserved" 1602 "Reserved" 1603 "Reserved" 1604 "Reserved" 1605 "Reserved" 1606 "Reserved" 1607 "Reserved" 1608 "Reserved" 1609 "Reserved" 1610 "Reserved" 1611 "Reserved" 1612 "Reserved" 1613 "Reserved" 1614 "Reserved" 1615 "Reserved" 1616 "Reserved" 1617 "Reserved" 1618 "Reserved" 1619 "Reserved" 1620 "Reserved" 1621 "Reserved" 1622 "Reserved" 1623 "Reserved" 1624 "Reserved" 1625 "Reserved" 1626 "Reserved" 1627 "Reserved" 1628 "Reserved" 1629 "Reserved" 1630 "Reserved" 1631 "Reserved" 1632 "Reserved" 1633 "Reserved" 1634 "Reserved" 1635 "Reserved" 1636 "Reserved" 1637 "Reserved" 1638 "Reserved" 1639 "Reserved" 1640 "Reserved" 1641 "Reserved" 1642 "Reserved" 1643 "Reserved" 1644 "Reserved" 1645 "Reserved" 1646 "Reserved" 1647 "Reserved" 1648 "Reserved" 1649 "Reserved" 1650 "Reserved" 1651 "Reserved" 1652 "Reserved" 1653 "Reserved" 1654 "Reserved" 1655 "Reserved" 1656 "Reserved" 1657 "Reserved" 1658 "Reserved" 1659 "Reserved" 1660 "Reserved" 1661 "Reserved" 1662 "Reserved" 1663 "Reserved" 1664 "Reserved" 1665 "Reserved" 1666 "Reserved" 1667 "Reserved" 1668 "Reserved" 1669 "Reserved" 1670 "Reserved" 1671 "Reserved" 1672 "Reserved" 1673 "Reserved" 1674 "Reserved" 1675 "Reserved" 1676 "Reserved" 1677 "Reserved" 1678 "Reserved" 1679 "Reserved" 1680 "Reserved" 1681 "Reserved" 1682 "Reserved" 1683 "Reserved" 1684 "Reserved" 1685 "Reserved" 1686 "Reserved" 1687 "Reserved" 1688 "Reserved" 1689 "Reserved" 1690 "Reserved" 1691 "Reserved" 1692 "Reserved" 1693 "Reserved" 1694 "Reserved" 1695 "Reserved" 1696 "Reserved" 1697 "Reserved" 1698 "Reserved" 1699 "Reserved" 1700 "Reserved" 1701 "Reserved" 1702 "Reserved" 1703 "Reserved" 1704 "Reserved" 1705 "Reserved" 1706 "Reserved" 1707 "Reserved" 1708 "Reserved" 1709 "Reserved" 1710 "Reserved" 1711 "Reserved" 1712 "Reserved" 1713 "Reserved" 1714 "Reserved" 1715 "Reserved" 1716 "Reserved" 1717 "Reserved" 1718 "Reserved" 1719 "Reserved" 1720 "Reserved" 1721 "Reserved" 1722 "Reserved" 1723 "Reserved" 1724 "Reserved" 1725 "Reserved" 1726 "Reserved" 1727 "Reserved" 1728 "Reserved" 1729 "Reserved" 1730 "Reserved" 1731 "Reserved" 1732 "Reserved" 1733 "Reserved" 1734 "Reserved" 1735 "Reserved" 1736 "Reserved" 1737 "Reserved" 1738 "Reserved" 1739 "Reserved" 1740 "Reserved" 1741 "Reserved" 1742 "Reserved" 1743 "Reserved" 1744 "Reserved" 1745 "Reserved" 1746 "Reserved" 1747 "Reserved" 1748 "Reserved" 1749 "Reserved" 1750 "Reserved" 1751 "Reserved" 1752 "Reserved" 1753 "Reserved" 1754 "Reserved" 1755 "Reserved" 1756 "Reserved" 1757 "Reserved" 1758 "Reserved" 1759 "Reserved" 1760 "Reserved" 1761 "Reserved" 1762 "Reserved" 1763 "Reserved" 1764 "Reserved" 1765 "Reserved" 1766 "Reserved" 1767 "Reserved" 1768 "Reserved" 1769 "Reserved" 1770 "Reserved" 1771 "Reserved" 1772 "Reserved" 1773 "Reserved" 1774 "Reserved" 1775 "Reserved" 1776 "Reserved" 1777 "Reserved" 1778 "Reserved" 1779 "Reserved" 1780 "Reserved" 1781 "Reserved" 1782 "Reserved" 1783 "Reserved" 1784 "Reserved" 1785 "Reserved" 1786 "Reserved" 1787 "Reserved" 1788 "Reserved" 1789 "Reserved" 1790 "Reserved" 1791 "Reserved" 1792 "Reserved" 1793 "Reserved" 1794 "Reserved" 1795 "Reserved" 1796 "Reserved" 1797 "Reserved" 1798 "Reserved" 1799 "Reserved" 1800 "Reserved" 1801 "Reserved" 1802 "Reserved" 1803 "Reserved" 1804 "Reserved" 1805 "Reserved" 1806 "Reserved" 1807 "Reserved" 1808 "Reserved" 1809 "Reserved" 1810 "Reserved" 1811 "Reserved" 1812 "Reserved" 1813 "Reserved" 1814 "Reserved" 1815 "Reserved" 1816 "Reserved" 1817 "Reserved" 1818 "Reserved" 1819 "Reserved" 1820 "Reserved" 1821 "Reserved" 1822 "Reserved" 1823 "Reserved" 1824 "Reserved" 1825 "Reserved" 1826 "Reserved" 1827 "Reserved" 1828 "Reserved" 1829 "Reserved" 1830 "Reserved" 1831 "Reserved" 1832 "Reserved" 1833 "Reserved" 1834 "Reserved" 1835 "Reserved" 1836 "Reserved" 1837 "Reserved" 1838 "Reserved" 1839 "Reserved" 1840 "Reserved" 1841 "Reserved" 1842 "Reserved" 1843 "Reserved" 1844 "Reserved" 1845 "Reserved" 1846 "Reserved" 1847 "Reserved" 1848 "Reserved" 1849 "Reserved" 1850 "Reserved" 1851 "Reserved" 1852 "Reserved" 1853 "Reserved" 1854 "Reserved" 1855 "Reserved" 1856 "Reserved" 1857 "Reserved" 1858 "Reserved" 1859 "Reserved" 1860 "Reserved" 1861 "Reserved" 1862 "Reserved" 1863 "Reserved" 1864 "Reserved" 1865 "Reserved" 1866 "Reserved" 1867 "Reserved" 1868 "Reserved" 1869 "Reserved" 1870 "Reserved" 1871 "Reserved" 1872 "Reserved" 1873 "Reserved" 1874 "Reserved" 1875 "Reserved" 1876 "Reserved" 1877 "Reserved" 1878 "Reserved" 1879 "Reserved" 1880 "Reserved" 1881 "Reserved" 1882 "Reserved" 1883 "Reserved" 1884 "Reserved" 1885 "Reserved" 1886 "Reserved" 1887 "Reserved" 1888 "Reserved" 1889 "Reserved" 1890 "Reserved" 1891 "Reserved" 1892 "Reserved" 1893 "Reserved" 1894 "Reserved" 1895 "Reserved" 1896 "Reserved" 1897 "Reserved" 1898 "Reserved" 1899 "Reserved" 1900 "Reserved" 1901 "Reserved" 1902 "Reserved" 1903 "Reserved" 1904 "Reserved" 1905 "Reserved" 1906 "Reserved" 1907 "Reserved" 1908 "Reserved" 1909 "Reserved" 1910 "Reserved" 1911 "Reserved" 1912 "Reserved" 1913 "Reserved" 1914 "Reserved" 1915 "Reserved" 1916 "Reserved" 1917 "Reserved" 1918 "Reserved" 1919 "Reserved" 1920 "Reserved" 1921 "Reserved" 1922 "Reserved" 1923 "Reserved" 1924 "Reserved" 1925 "Reserved" 1926 "Reserved" 1927 "Reserved" 1928 "Reserved" 1929 "Reserved" 1930 "Reserved" 1931 "Reserved" 1932 "Reserved" 1933 "Reserved" 1934 "Reserved" 1935 "Reserved" 1936 "Reserved" 1937 "Reserved" 1938 "Reserved" 1939 "Reserved" 1940 "Reserved" 1941 "Reserved" 1942 "Reserved" 1943 "Reserved" 1944 "Reserved" 1945 "Reserved" 1946 "Reserved" 1947 "Reserved" 1948 "Reserved" 1949 "Reserved" 1950 "Reserved" 1951 "Reserved" 1952 "Reserved" 1953 "Reserved" 1954 "Reserved" 1955 "Reserved" 1956 "Reserved" 1957 "Reserved" 1958 "Reserved" 1959 "Reserved" 1960 "Reserved" 1961 "Reserved" 1962 "Reserved" 1963 "Reserved" 1964 "Reserved" 1965 "Reserved" 1966 "Reserved" 1967 "Reserved" 1968 "Reserved" 1969 "Reserved" 1970 "Reserved" 1971 "Reserved" 1972 "Reserved" 1973 "Reserved" 1974 "Reserved" 1975 "Reserved" 1976 "Reserved" 1977 "Reserved" 1978 "Reserved" 1979 "Reserved" 1980 "Reserved" 1981 "Reserved" 1982 "Reserved" 1983 "Reserved" 1984 "Reserved" 1985 "Reserved" 1986 "Reserved" 1987 "Reserved" 1988 "Reserved" 1989 "Reserved" 1990 "Reserved" 1991 "Reserved" 1992 "Reserved" 1993 "Reserved" 1994 "Reserved" 1995 "Reserved" 1996 "Reserved" 1997 "Reserved" 1998 "Reserved" 1999 "Reserved" 2000 "Reserved" 2001 "Reserved" 2002 "Reserved" 2003 "Reserved" 2004 "Reserved" 2005 "Reserved" 2006 "Reserved" 2007 "Reserved" 2008 "Reserved" 2009 "Reserved" 2010 "Reserved" 2011 "Reserved" 2012 "Reserved" 2013 "Reserved" 2014 "Reserved" 2015 "Reserved" 2016 "Reserved" 2017 "Reserved" 2018 "Reserved" 2019 "Reserved" 2020 "Reserved" 2021 "Reserved" 2022 "Reserved" 2023 "Reserved" 2024 "Reserved" 2025 "Reserved" 2026 "Reserved" 2027 "Reserved" 2028 "Reserved" 2029 "Reserved" 2030 "Reserved" 2031 "Reserved" 2032 "Reserved" 2033 "Reserved" 2034 "Reserved" 2035 "Reserved" 2036 "Reserved" 2037 "Reserved" 2038 "Reserved" 2039 "Reserved" 2040 "Reserved" 2041 "Reserved" 2042 "Reserved" 2043 "Reserved" 2044 "Reserved" 2045 "Reserved" 2046 "Reserved" 2047 "Reserved" ;
VAL_ 1057 SCCFailInfo 0 "System without error" 1 "Performance degredation" 2 "System temporairy unavailable" 3 "SCC Service Required" ;
VAL_ 1057 SCCMode 0 "Off" 1 "Engaged" 2 "Override" 3 "Shutoff" ;
VAL_ 1057 StopReq 0 "No request" 1 "Stop control is required" ;
VAL_ 1057 TakeOverReq 0 "No takeover request" 1 "Takeover request" ;
VAL_ 1290 SCC_Equip 0 "Not Applied" 1 "Applied" ;
VAL_ 1290 SCCDrvModeRValue 0 "Default" 1 "Comford Mode" 2 "Normal Mode" 3 "Dynamic Mode" 4 "Reserved" 5 "Reserved" 6 "Reserved" 7 "Invalid" ;
VAL_ 905 NSCC_AutoSetSpdSta 0 "Auto Set Speed Off" 1 "Auto Set Speed On" 2 "Reserved" 3 "Error Indicator" ;
VAL_ 905 NSCC_AutoSetSpdUpdtSta 0 "Auto Set Speed Update Off" 1 "Auto Set Speed Update On" 2 "Reserved" 3 "Error Indicator" ;
VAL_ 905 NSCC_InfoPUDis 0 "None" 1 "NSCC Warning" 2 "Reserved" 3 "Reserved" 4 "Reserved" 5 "Reserved" 6 "Reserved" 7 "Reserved" ;
VAL_ 905 ObjGap 0 "No in-path object detected" 1 "Distance warning" 2 "1st level object distance" 3 "2nd level object distance" 4 "3rd level object distance" 5 "4th level object distance" 6 "reserved" 7 "reserved" 8 "reserved" 9 "reserved" 10 "reserved" 11 "reserved" 12 "reserved" 13 "reserved" 14 "reserved" 15 "reserved" 16 "reserved" 17 "reserved" 18 "reserved" 19 "reserved" 20 "reserved" 21 "reserved" 22 "reserved" 23 "reserved" 24 "reserved" 25 "reserved" 26 "reserved" 27 "reserved" 28 "reserved" 29 "reserved" 30 "reserved" 31 "reserved" 32 "reserved" 33 "reserved" 34 "reserved" 35 "reserved" 36 "reserved" 37 "reserved" 38 "reserved" 39 "reserved" 40 "reserved" 41 "reserved" 42 "reserved" 43 "reserved" 44 "reserved" 45 "reserved" 46 "reserved" 47 "reserved" 48 "reserved" 49 "reserved" 50 "reserved" 51 "reserved" 52 "reserved" 53 "reserved" 54 "reserved" 55 "reserved" 56 "reserved" 57 "reserved" 58 "reserved" 59 "reserved" 60 "reserved" 61 "reserved" 62 "reserved" 63 "reserved" 64 "reserved" 65 "reserved" 66 "reserved" 67 "reserved" 68 "reserved" 69 "reserved" 70 "reserved" 71 "reserved" 72 "reserved" 73 "reserved" 74 "reserved" 75 "reserved" 76 "reserved" 77 "reserved" 78 "reserved" 79 "reserved" 80 "reserved" 81 "reserved" 82 "reserved" 83 "reserved" 84 "reserved" 85 "reserved" 86 "reserved" 87 "reserved" 88 "reserved" 89 "reserved" 90 "reserved" 91 "reserved" 92 "reserved" 93 "reserved" 94 "reserved" 95 "reserved" 96 "reserved" 97 "reserved" 98 "reserved" 99 "reserved" 100 "reserved" 101 "reserved" 102 "reserved" 103 "reserved" 104 "reserved" 105 "reserved" 106 "reserved" 107 "reserved" 108 "reserved" 109 "reserved" 110 "reserved" 111 "reserved" 112 "reserved" 113 "reserved" 114 "reserved" 115 "reserved" 116 "reserved" 117 "reserved" 118 "reserved" 119 "reserved" 120 "reserved" 121 "reserved" 122 "reserved" 123 "reserved" 124 "reserved" 125 "reserved" 126 "reserved" 127 "reserved" 128 "reserved" 129 "reserved" 130 "reserved" 131 "reserved" 132 "reserved" 133 "reserved" 134 "reserved" 135 "reserved" 136 "reserved" 137 "reserved" 138 "reserved" 139 "reserved" 140 "reserved" 141 "reserved" 142 "reserved" 143 "reserved" 144 "reserved" 145 "reserved" 146 "reserved" 147 "reserved" 148 "reserved" 149 "reserved" 150 "reserved" 151 "reserved" 152 "reserved" 153 "reserved" 154 "reserved" 155 "reserved" 156 "reserved" 157 "reserved" 158 "reserved" 159 "reserved" 160 "reserved" 161 "reserved" 162 "reserved" 163 "reserved" 164 "reserved" 165 "reserved" 166 "reserved" 167 "reserved" 168 "reserved" 169 "reserved" 170 "reserved" 171 "reserved" 172 "reserved" 173 "reserved" 174 "reserved" 175 "reserved" 176 "reserved" 177 "reserved" 178 "reserved" 179 "reserved" 180 "reserved" 181 "reserved" 182 "reserved" 183 "reserved" 184 "reserved" 185 "reserved" 186 "reserved" 187 "reserved" 188 "reserved" 189 "reserved" 190 "reserved" 191 "reserved" 192 "reserved" 193 "reserved" 194 "reserved" 195 "reserved" 196 "reserved" 197 "reserved" 198 "reserved" 199 "reserved" 200 "reserved" 201 "reserved" 202 "reserved" 203 "reserved" 204 "reserved" 205 "reserved" 206 "reserved" 207 "reserved" 208 "reserved" 209 "reserved" 210 "reserved" 211 "reserved" 212 "reserved" 213 "reserved" 214 "reserved" 215 "reserved" 216 "reserved" 217 "reserved" 218 "reserved" 219 "reserved" 220 "reserved" 221 "reserved" 222 "reserved" 223 "reserved" 224 "reserved" 225 "reserved" 226 "reserved" 227 "reserved" 228 "reserved" 229 "reserved" 230 "reserved" 231 "reserved" 232 "reserved" 233 "reserved" 234 "reserved" 235 "reserved" 236 "reserved" 237 "reserved" 238 "reserved" 239 "reserved" 240 "reserved" 241 "reserved" 242 "reserved" 243 "reserved" 244 "reserved" 245 "reserved" 246 "reserved" 247 "reserved" 248 "reserved" 249 "reserved" 250 "reserved" 251 "reserved" 252 "reserved" 253 "reserved" 254 "reserved" 255 "reserved" ;
VAL_ 905 SCC_NSCCOnOffSta 0 "Default" 1 "Off" 2 "On" 3 "Invalid" ;
VAL_ 905 SCC_ObjSta 0 "No in-path object detected" 1 "In-path object detected (uncontrollable)" 2 "In-path object detected (controllable: longitudinal)" 3 "Reserved" ;
VAL_ 905 SCC14_AliveCounter 15 "Signal Invalid" ;
VAL_ 905 SCCMode2 0 "Off" 1 "Engaged" 2 "Override" 3 "Shutoff" 4 "Canceled" ;
VAL_ 339 ABS_ACT 0 "ABS control inactive" 1 "ABS control active" ;
VAL_ 339 ABS_DIAG 0 "ABS/TCS/ESC is not diagnostic mode" 1 "ABS/TCS/ESC is diagnostic mode" ;
VAL_ 339 ESP_CTL 1 "ESC active" ;
VAL_ 339 ESP_PAS 1 "ESC disabled by user (SW off)" ;
VAL_ 339 TCS_CTL 1 "TCS Active" ;
VAL_ 339 TCS_DEF 1 "TCS is defective (failed)" ;
VAL_ 339 TCS_PAS 1 "TCS is disabled by user" ;
VAL_ 916 CF_VSM_Avail 0 "Available" 1 "Temporarily not Available" 2 "Permanently not Available" 3 "FCA Communication Error" ;
VAL_ 916 DriverOverride 0 "No override" 1 "Override by acceleration pedal" 2 "Override by deceleration" 3 "Not defined" ;
VAL_ 916 FCA_CODED_STAT 0 "Not Coded" 1 "Coding Completed" ;
VAL_ 916 FCA_EQUIP 0 "FCA is not equipped" 1 "FCA is equipped" ;
VAL_ 916 PBRAKE_ACT 0 "Parking brake is not activated" 1 "Parking brake is activated" ;
VAL_ 916 SCC_CODED_STAT 0 "Not Coded" 1 "Coding Completed" ;
VAL_ 916 SCC_EQUIP 0 "SCC is not equipped" 1 "SCC is equipped" ;
VAL_ 916 SCCEnable 0 "SCC enabled" 1 "SCC disabled reversible" 2 "SCC disabled irreversible" 3 "SCC disabled irreversible due to communication error" ;
VAL_ 916 StandStill 0 "No stand still detected" 1 "Stand still detected" ;
VAL_ 916 DriverBraking 0 "Brake pedal not pressed" 1 "Brake pedal pressed" ;
VAL_ 356 CF_Esc_Act 0 "VSM control inactive0H" 1 "VSM control active" ;
SIG_GROUP_ 1057 SCC12 1 : aReqRaw aReqValue CR_VSM_Alive CR_VSM_ChkSum SCC_TrgtDstVal SCCFailInfo SCCMode StopReq TakeOverReq;
SIG_GROUP_ 1290 SCC13 1 : SCC_Equip SCCDrvModeRValue;
SIG_GROUP_ 905 SCC14 1 : ComfortBandLower ComfortBandUpper JerkLowerLimit JerkUpperLimit NSCC_AutoSetSpdSta NSCC_AutoSetSpdUpdtSta NSCC_InfoPUDis ObjGap SCC_NSCCOnOffSta SCC_ObjSta SCC14_AliveCounter SCC14_ChkSum SCCMode2;
SIG_GROUP_ 339 TCS11 1 : ABS_ACT ABS_DIAG AliveCounter_TCS1 CheckSum_TCS1 ESP_CTL ESP_PAS TCS_CTL TCS_DEF TCS_PAS;
SIG_GROUP_ 916 TCS13 1 : AliveCounterTCS CF_VSM_Avail CheckSum_TCS3 DriverOverride FCA_CODED_STAT FCA_EQUIP PBRAKE_ACT SCC_CODED_STAT SCC_EQUIP SCCEnable StandStill DriverBraking;
SIG_GROUP_ 356 VSM11_FS 1 : CF_Esc_Act CRC;
SIG_GROUP_ 902 WHL_SPD11 1 : WHL_SPD_AliveCounter_LSB WHL_SPD_AliveCounter_MSB WHL_SPD_Checksum_LSB WHL_SPD_Checksum_MSB WHL_SPD_FL WHL_SPD_FR WHL_SPD_RL WHL_SPD_RR;
SIG_GROUP_ 1728 XCP_Rx_Pdu 1 : XCP_Rx_Data;
SIG_GROUP_ 1729 XCP_Tx_Pdu 1 : XCP_Tx_Data;
